# TC37X register map
File version: 1.0.0
CPU: CM4 r0p1, little endian, MPU, FPU, VTOR, 3 interrupt priority bits
Registers are 16-bit, read-write, reset 0x0 unless marked. A register's access mark holds for its fields unless they carry their own. Offsets are from the block's base; lines under a group give offsets from that group; [hi:lo] are bit positions; {n}, {i} and the like mark numbered series; 'fields as' and 'values as' point back to an identical list; <NAME> marks a mode.

## Memory map
0x50000000 CPU2 size 0x18000 — ce_cpu
0x60000000 CPU1 size 0x3C000 — ce_cpu
0x70000000 CPU0 size 0x3C000 — ce_cpu
0xA8080000 PFI0 size 0x80000 — ce_pfi
0xA8380000 PFI1 size 0x80000 — ce_pfi
0xF0000400 CBS size 0x200 — ce_cbs
{0xF0000600+0x100*n} ASCLIN{n} size 0x100 (n=0..9) — ce_asclin
0xF0001000 STM0 size 0x100 — ce_stm
0xF0001100 STM1 size 0x100 — ce_stm
0xF0001200 STM2 size 0x100 — ce_stm
0xF0001800 GPT120 size 0x100 — ce_gptonetwo
0xF0002600 MSC0 size 0x100 — ce_msc64
0xF0002700 MSC1 size 0x100 — ce_msc64
0xF0002A00 CCU60 size 0x100 — ce_ccusix
0xF0002B00 CCU61 size 0x100 — ce_ccusix
0xF0010000 DMA size 0x4000 — ce_sadma
0xF0020000 EVADC size 0x4000 — ce_evadc
0xF0024000 EDSADC size 0x1000 — ce_edsadc
0xF0025000 CONVCTRL size 0x100 — ce_convctrl
0xF0035000 IOM size 0x200 — ce_iom
0xF0036000 SCU size 0x400 — ystem Control Unit
0xF0036800 SMU size 0x800 — ce_smu
0xF0037000 INT size 0x1000 — ce_int
0xF0038000 SRC size 0x2000 — ce_src
0xF003A000 port_00 size 0x100 — eneral Purpose I/O Ports and Peripheral I/O Lines
0xF003A100 port_01 size 0x100 — eneral Purpose I/O Ports and Peripheral I/O Lines
0xF003A200 port_02 size 0x100 — eneral Purpose I/O Ports and Peripheral I/O Lines
0xF003AA00 port_10 size 0x100 — eneral Purpose I/O Ports and Peripheral I/O Lines
0xF003AB00 port_11 size 0x100 — eneral Purpose I/O Ports and Peripheral I/O Lines
0xF003AC00 port_12 size 0x100 — eneral Purpose I/O Ports and Peripheral I/O Lines
0xF003AD00 port_13 size 0x100 — eneral Purpose I/O Ports and Peripheral I/O Lines
0xF003AE00 port_14 size 0x100 — eneral Purpose I/O Ports and Peripheral I/O Lines
0xF003AF00 port_15 size 0x100 — eneral Purpose I/O Ports and Peripheral I/O Lines
0xF003B400 port_20 size 0x100 — eneral Purpose I/O Ports and Peripheral I/O Lines
0xF003B500 port_21 size 0x100 — eneral Purpose I/O Ports and Peripheral I/O Lines
0xF003B600 port_22 size 0x100 — eneral Purpose I/O Ports and Peripheral I/O Lines
0xF003B700 port_23 size 0x100 — eneral Purpose I/O Ports and Peripheral I/O Lines
0xF003C000 port_32 size 0x100 — eneral Purpose I/O Ports and Peripheral I/O Lines
0xF003C100 port_33 size 0x100 — eneral Purpose I/O Ports and Peripheral I/O Lines
0xF003C200 port_34 size 0x100 — eneral Purpose I/O Ports and Peripheral I/O Lines
0xF003C800 port_40 size 0x100 — eneral Purpose I/O Ports and Peripheral I/O Lines
0xF0060000 MTU size 0x10000 — ce_mtu
0xF0200000 CAN0 size 0x9000 — ce_mc_m_can
0xF0210000 CAN1 size 0x9000 — ce_mc_m_can
0xF0248000 PMS size 0x200 — ce_pms
0xF02C0A00 ASCLIN10 size 0x100 — ce_asclin
0xF02C0B00 ASCLIN11 size 0x100 — ce_asclin
0xF8030000 FSI size 0x100 — ce_fsi
0xF8038000 PMU size 0x8000 — ce_pmu
0xF8040000 DMU size 0x40000 — ce_dmu
0xF8500000 DAM0 size 0x8000 — ce_dam
0xF8508000 AMU00 size 0x100 — ce_amu
0xF8508100 AMU01 size 0x100 — ce_amu
0xF8508400 ADMA0 size 0x100 — ce_adma
0xF8700000 DOM0 size 0x10000 — ce_dom
0xFB718000 MINIMCDS size 0x8000 — ce_minimcds

## Interrupts
{n} __interrupt_handler_{n} (SRC) (n=0..31) — Interrupt {n} entry

## PFI0 — ce_pfi
Base 0xA8080000
Same registers: PFI1 0xA8380000
0x00 ECCR 32-bit ro — ECC Read Register
  [21:0] RCODE — Error Correction Read Code - RCODE
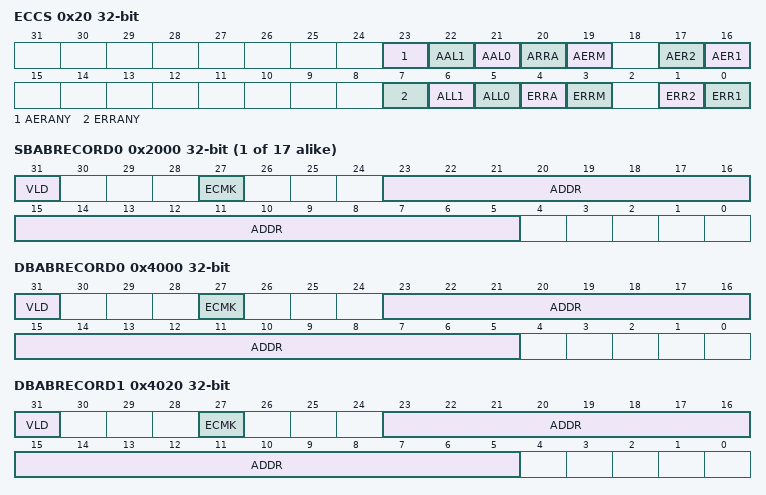
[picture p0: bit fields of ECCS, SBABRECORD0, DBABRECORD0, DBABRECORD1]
0x20 ECCS 32-bit ro — ECC Status Register
  [23] AERANY — Accumulated Any Read Access ECC Error - AERANY
  [22] AAL1 — Accumulated All Ones - AAL1
  [21] AAL0 — Accumulated All Zeros - AAL0
  [20] ARRA — Accumulated ECC Error Within the Address - ARRA
  [19] AERM — Accumulated Multi-bit ECC Errors - AERM
  [17] AER2 — Accumulated Double Bit ECC Errors - AER2
  [16] AER1 — Accumulated Single Bit ECC Errors - AER1
  [7] ERRANY — Any Read Access ECC Error - ERRANY
  [6] ALL1 — All Ones - ALL1
  [5] ALL0 — Read Access All Zeros - ALL0
  [4] ERRA — Read Access ECC Error Within the Address - ERRA
  [3] ERRM — Read Access Multi-bit ECC Error - ERRM
  [1] ERR2 — Read Access Double Bit ECC Error - ERR2
  [0] ERR1 — Read Access Single Bit ECC Error - ERR1
{0x2000+0x20*i} SBABRECORD{i} 32-bit ro (i=0..16)
  [31] VLD — Valid - VLD
  [27] ECMK — Erase Counter Marker - ECMK
  [23:5] ADDR — Address - ADDR
0x4000 DBABRECORD0 32-bit ro
  fields as SBABRECORD0
0x4020 DBABRECORD1 32-bit ro
  fields as SBABRECORD0
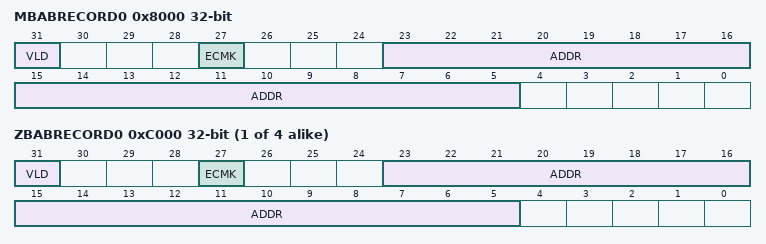
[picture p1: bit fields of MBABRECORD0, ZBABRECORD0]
0x8000 MBABRECORD0 32-bit ro
  fields as SBABRECORD0
{0xC000+0x20*i} ZBABRECORD{i} 32-bit ro (i=0..3)
  fields as SBABRECORD0
